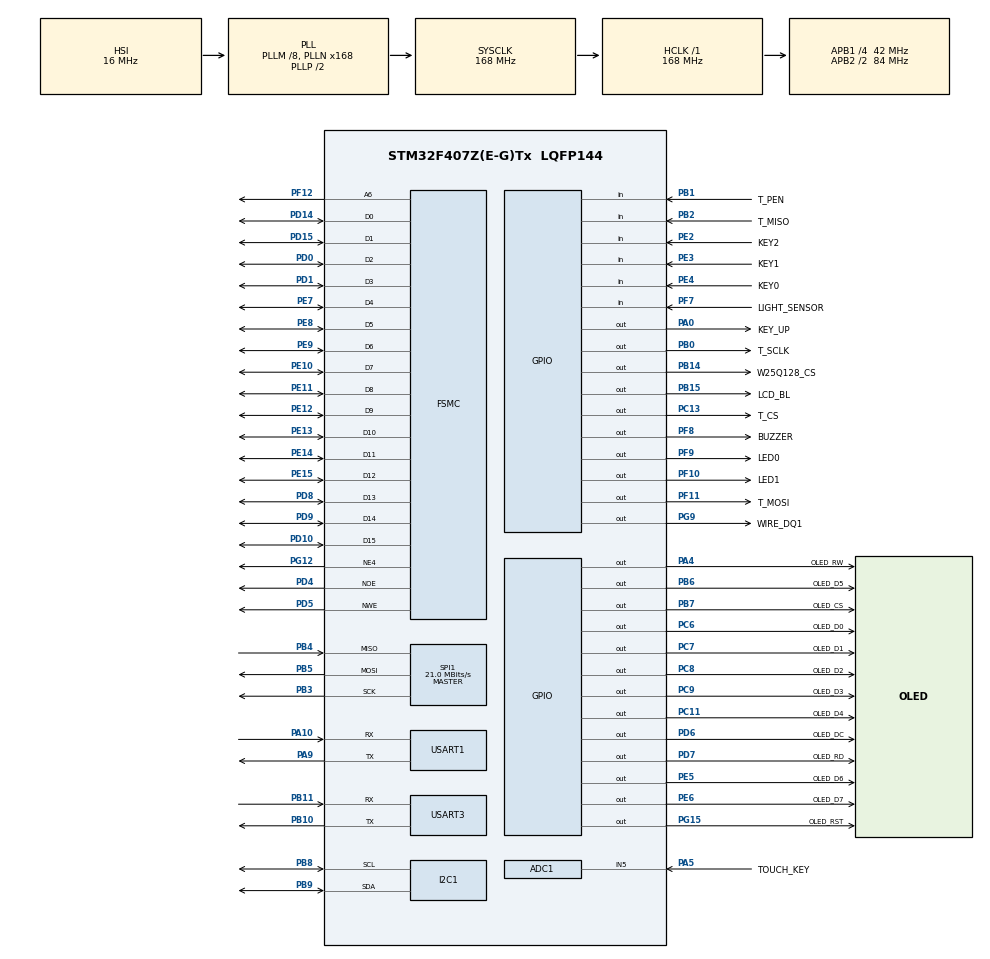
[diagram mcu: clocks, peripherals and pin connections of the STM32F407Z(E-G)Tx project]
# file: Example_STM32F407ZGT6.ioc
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ADC1.Channel-0\#ChannelRegularConversion=ADC_CHANNEL_5
ADC1.NbrOfConversionFlag=1
ADC1.Rank-0\#ChannelRegularConversion=1
ADC1.SamplingTime-0\#ChannelRegularConversion=ADC_SAMPLETIME_480CYCLES
ADC1.master=1
FSMC.BusTurnAroundDuration4=0
FSMC.DataSetupTime4=60
FSMC.ExtendedAddressSetupTime4=9
FSMC.ExtendedDataSetupTime4=9
FSMC.ExtendedMode4=FSMC_EXTENDED_MODE_ENABLE
Mcu.Family=STM32F4
Mcu.Name=STM32F407Z(E-G)Tx
Mcu.Package=LQFP144
NVIC.PriorityGroup=NVIC_PRIORITYGROUP_4
NVIC.USART1_IRQn=true\:0\:0\:false\:false\:true\:true\:true\:true
NVIC.USART3_IRQn=true\:0\:0\:false\:false\:true\:true\:true\:true
PA0-WKUP.GPIO_Label=KEY_UP
PA0-WKUP.Signal=GPIO_Output
PA10.Mode=Asynchronous
PA10.Signal=USART1_RX
PA13.Mode=Serial_Wire
PA13.Signal=SYS_JTMS-SWDIO
PA14.Mode=Serial_Wire
PA14.Signal=SYS_JTCK-SWCLK
PA4.GPIO_Label=OLED_RW
PA4.Signal=GPIO_Output
PA5.GPIO_Label=TOUCH_KEY
PA5.Signal=ADCx_IN5
PA9.Mode=Asynchronous
PA9.Signal=USART1_TX
PB0.GPIO_Label=T_SCLK
PB0.GPIO_PuPd=GPIO_PULLUP
PB0.GPIO_Speed=GPIO_SPEED_FREQ_HIGH
PB0.Signal=GPIO_Output
PB1.GPIO_Label=T_PEN
PB1.GPIO_PuPd=GPIO_PULLUP
PB1.Signal=GPIO_Input
PB10.Mode=Asynchronous
PB10.Signal=USART3_TX
PB11.Mode=Asynchronous
PB11.Signal=USART3_RX
PB14.GPIO_Label=W25Q128_CS
PB14.Signal=GPIO_Output
PB15.GPIO_Label=LCD_BL
PB15.Signal=GPIO_Output
PB2.GPIO_Label=T_MISO
PB2.GPIO_PuPd=GPIO_PULLUP
PB2.Signal=GPIO_Input
PB3.Mode=Full_Duplex_Master
PB3.Signal=SPI1_SCK
PB4.Mode=Full_Duplex_Master
PB4.Signal=SPI1_MISO
PB5.Mode=Full_Duplex_Master
PB5.Signal=SPI1_MOSI
PB6.GPIO_Label=OLED_D5
PB6.Signal=GPIO_Output
PB7.GPIO_Label=OLED_CS
PB7.Signal=GPIO_Output
PB8.Mode=I2C
PB8.Signal=I2C1_SCL
PB9.Mode=I2C
PB9.Signal=I2C1_SDA
PC11.GPIO_Label=OLED_D4
PC11.Signal=GPIO_Output
PC13-ANTI_TAMP.GPIO_Label=T_CS
PC13-ANTI_TAMP.GPIO_PuPd=GPIO_PULLUP
PC13-ANTI_TAMP.GPIO_Speed=GPIO_SPEED_FREQ_LOW
PC13-ANTI_TAMP.PinState=GPIO_PIN_RESET
PC13-ANTI_TAMP.Signal=GPIO_Output
PC6.GPIO_Label=OLED_D0
PC6.Signal=GPIO_Output
PC7.GPIO_Label=OLED_D1
PC7.Signal=GPIO_Output
PC8.GPIO_Label=OLED_D2
PC8.Signal=GPIO_Output
PC9.GPIO_Label=OLED_D3
PC9.Signal=GPIO_Output
PD0.Signal=FSMC_D2_DA2
PD1.Signal=FSMC_D3_DA3
PD10.Signal=FSMC_D15_DA15
PD14.Signal=FSMC_D0_DA0
PD15.Signal=FSMC_D1_DA1
PD4.Signal=FSMC_NOE
PD5.Signal=FSMC_NWE
PD6.GPIO_Label=OLED_DC
PD6.Signal=GPIO_Output
PD7.GPIO_Label=OLED_RD
PD7.Signal=GPIO_Output
PD8.Signal=FSMC_D13_DA13
PD9.Signal=FSMC_D14_DA14
PE10.Signal=FSMC_D7_DA7
PE11.Signal=FSMC_D8_DA8
PE12.Signal=FSMC_D9_DA9
PE13.Signal=FSMC_D10_DA10
PE14.Signal=FSMC_D11_DA11
PE15.Signal=FSMC_D12_DA12
PE2.GPIO_Label=KEY2
PE2.Signal=GPIO_Input
PE3.GPIO_Label=KEY1
PE3.Signal=GPIO_Input
PE4.GPIO_Label=KEY0
PE4.Signal=GPIO_Input
PE5.GPIO_Label=OLED_D6
PE5.Signal=GPIO_Output
PE6.GPIO_Label=OLED_D7
PE6.Signal=GPIO_Output
PE7.Signal=FSMC_D4_DA4
PE8.Signal=FSMC_D5_DA5
PE9.Signal=FSMC_D6_DA6
PF10.GPIO_Label=LED1
PF10.Signal=GPIO_Output
PF11.GPIO_Label=T_MOSI
PF11.GPIO_PuPd=GPIO_PULLUP
PF11.GPIO_Speed=GPIO_SPEED_FREQ_HIGH
PF11.Signal=GPIO_Output
PF12.Signal=FSMC_A6
PF7.GPIO_Label=LIGHT_SENSOR
PF7.Signal=GPIO_Input
PF8.GPIO_Label=BUZZER
PF8.Signal=GPIO_Output
PF9.GPIO_Label=LED0
PF9.Signal=GPIO_Output
PG12.Mode=NorPsramChipSelect4_4
PG12.Signal=FSMC_NE4
PG15.GPIO_Label=OLED_RST
PG15.Signal=GPIO_Output
PG9.GPIO_Label=WIRE_DQ1
PG9.Signal=GPIO_Output
PH0-OSC_IN.Mode=HSE-External-Oscillator
PH0-OSC_IN.Signal=RCC_OSC_IN
PH1-OSC_OUT.Mode=HSE-External-Oscillator
PH1-OSC_OUT.Signal=RCC_OSC_OUT
ProjectManager.HeapSize=0x200
ProjectManager.StackSize=0x400
ProjectManager.TargetToolchain=CMake
RCC.48MHZClocksFreq_Value=84000000
RCC.AHBFreq_Value=168000000
RCC.APB1CLKDivider=RCC_HCLK_DIV4
RCC.APB1Freq_Value=42000000
RCC.APB1TimFreq_Value=84000000
RCC.APB2CLKDivider=RCC_HCLK_DIV2
RCC.APB2Freq_Value=84000000
RCC.APB2TimFreq_Value=168000000
RCC.CortexFreq_Value=168000000
RCC.HCLKFreq_Value=168000000
RCC.HSE_VALUE=25000000
RCC.HSI_VALUE=16000000
RCC.LSE_VALUE=32768
RCC.PLLM=8
RCC.PLLN=168
RCC.SYSCLKFreq_VALUE=168000000
RCC.SYSCLKSource=RCC_SYSCLKSOURCE_PLLCLK
RCC.VCOOutputFreq_Value=336000000
SH.ADCx_IN5.0=ADC1_IN5,IN5
SH.FSMC_A6.0=FSMC_A6,A6_4
SH.FSMC_D0_DA0.0=FSMC_D0,16b-d4
SH.FSMC_D10_DA10.0=FSMC_D10,16b-d4
SH.FSMC_D11_DA11.0=FSMC_D11,16b-d4
SH.FSMC_D12_DA12.0=FSMC_D12,16b-d4
SH.FSMC_D13_DA13.0=FSMC_D13,16b-d4
SH.FSMC_D14_DA14.0=FSMC_D14,16b-d4
SH.FSMC_D15_DA15.0=FSMC_D15,16b-d4
SH.FSMC_D1_DA1.0=FSMC_D1,16b-d4
SH.FSMC_D2_DA2.0=FSMC_D2,16b-d4
SH.FSMC_D3_DA3.0=FSMC_D3,16b-d4
SH.FSMC_D4_DA4.0=FSMC_D4,16b-d4
SH.FSMC_D5_DA5.0=FSMC_D5,16b-d4
SH.FSMC_D6_DA6.0=FSMC_D6,16b-d4
SH.FSMC_D7_DA7.0=FSMC_D7,16b-d4
SH.FSMC_D8_DA8.0=FSMC_D8,16b-d4
SH.FSMC_D9_DA9.0=FSMC_D9,16b-d4
SH.FSMC_NOE.0=FSMC_NOE,Lcd4
SH.FSMC_NWE.0=FSMC_NWE,Lcd4
SPI1.BaudRatePrescaler=SPI_BAUDRATEPRESCALER_4
SPI1.CLKPhase=SPI_PHASE_2EDGE
SPI1.CLKPolarity=SPI_POLARITY_HIGH
SPI1.CalculateBaudRate=21.0 MBits/s
SPI1.Direction=SPI_DIRECTION_2LINES
SPI1.Mode=SPI_MODE_MASTER
SPI1.VirtualType=VM_MASTER
TIM6.Period=1000-1
TIM6.Prescaler=168-1
USART1.VirtualMode=VM_ASYNC
USART3.VirtualMode=VM_ASYNC
VP_TIM6_VS_ClockSourceINT.Mode=Enable_Timer
board=custom

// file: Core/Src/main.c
/* USER CODE BEGIN Header */
/**
  ******************************************************************************
  * @file           : main.c
  * @brief          : Main program body
  ******************************************************************************
  * @attention
  *
  * Copyright (c) 2026 STMicroelectronics.
  * All rights reserved.
  *
  * This software is licensed under terms that can be found in the LICENSE file
  * in the root directory of this software component.
  * If no LICENSE file comes with this software, it is provided AS-IS.
  *
  ******************************************************************************
  */
/* USER CODE END Header */
#include "main.h"
#include "adc.h"
#include "i2c.h"
#include "spi.h"
#include "tim.h"
#include "usart.h"
#include "gpio.h"
#include "fsmc.h"

/* USER CODE BEGIN Includes */
#include <stdio.h>

#include "app_debug.h"
#include "led.h"
#include "tft_lcd.h"
#include "page_manager.h"
/* USER CODE END Includes */

void SystemClock_Config(void);

int main(void)
{

  /* MCU Configuration--------------------------------------------------------*/

  /* Reset of all peripherals, Initializes the Flash interface and the Systick. */
  HAL_Init();

  /* Configure the system clock */
  SystemClock_Config();

  /* Initialize all configured peripherals */
  MX_GPIO_Init();
  MX_ADC1_Init();
  MX_USART1_UART_Init();
  MX_TIM6_Init();
  MX_FSMC_Init();
  MX_USART3_UART_Init();
  MX_SPI1_Init();
  MX_I2C1_Init();
  /* USER CODE BEGIN 2 */
  Leds_Init();

  TFTLCD_Init();
  TFTLCD_BackLight(1);

  Touch_Init();
  PageManager_Init();
  /* USER CODE END 2 */

  /* Infinite loop */
  /* USER CODE BEGIN WHILE */
  while (1)
  {
    PageManager_Loop();

    /* USER CODE END WHILE */

  }
}

void SystemClock_Config(void)
{
  RCC_OscInitTypeDef RCC_OscInitStruct = {0};
  RCC_ClkInitTypeDef RCC_ClkInitStruct = {0};

  /** Configure the main internal regulator output voltage
  */
  __HAL_RCC_PWR_CLK_ENABLE();
  __HAL_PWR_VOLTAGESCALING_CONFIG(PWR_REGULATOR_VOLTAGE_SCALE1);

  /** Initializes the RCC Oscillators according to the specified parameters
  * in the RCC_OscInitTypeDef structure.
  */
  RCC_OscInitStruct.OscillatorType = RCC_OSCILLATORTYPE_HSI;
  RCC_OscInitStruct.HSIState = RCC_HSI_ON;
  RCC_OscInitStruct.HSICalibrationValue = RCC_HSICALIBRATION_DEFAULT;
  RCC_OscInitStruct.PLL.PLLState = RCC_PLL_ON;
  RCC_OscInitStruct.PLL.PLLSource = RCC_PLLSOURCE_HSI;
  RCC_OscInitStruct.PLL.PLLM = 8;
  RCC_OscInitStruct.PLL.PLLN = 168;
  RCC_OscInitStruct.PLL.PLLP = RCC_PLLP_DIV2;
  RCC_OscInitStruct.PLL.PLLQ = 4;
  if (HAL_RCC_OscConfig(&RCC_OscInitStruct) != HAL_OK)
  {
    Error_Handler();
  }

  /** Initializes the CPU, AHB and APB buses clocks
  */
  RCC_ClkInitStruct.ClockType = RCC_CLOCKTYPE_HCLK|RCC_CLOCKTYPE_SYSCLK
                              |RCC_CLOCKTYPE_PCLK1|RCC_CLOCKTYPE_PCLK2;
  RCC_ClkInitStruct.SYSCLKSource = RCC_SYSCLKSOURCE_PLLCLK;
  RCC_ClkInitStruct.AHBCLKDivider = RCC_SYSCLK_DIV1;
  RCC_ClkInitStruct.APB1CLKDivider = RCC_HCLK_DIV4;
  RCC_ClkInitStruct.APB2CLKDivider = RCC_HCLK_DIV2;

  if (HAL_RCC_ClockConfig(&RCC_ClkInitStruct, FLASH_LATENCY_5) != HAL_OK)
  {
    Error_Handler();
  }
}

void Error_Handler(void)
{
  __disable_irq();
  while (1)
  {
  }
}
